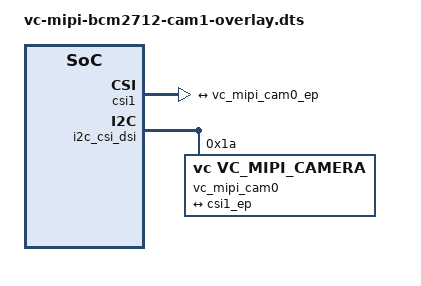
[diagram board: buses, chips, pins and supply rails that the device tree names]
//
// Definitions for cam 0 for RaspberryPi 5
//
// Copyright (C) 2024 - Florian Schmid, Vision Components GmbH
//




/dts-v1/;
/plugin/;

/ {    
	fragment@0 {
		target = <&csi1>;
		__overlay__ {
			status = "okay";

			port {
				csi1_ep: endpoint {
					remote-endpoint = <&vc_mipi_cam0_ep>;
					data-lanes = <1>;
				};
			};
		};
	};	
	fragment@1 {
		target = <&i2c_csi_dsi>;
		__overlay__ {
			#address-cells = <1>;
			#size-cells = <0>;
			status = "okay";

			vc_mipi_cam0: camera@1a {
				compatible = "vc,vc_mipi_camera";
				reg = <0x1a>;
				status = "okay";

				
				port {
					vc_mipi_cam0_ep: endpoint {
						remote-endpoint = <&csi1_ep>;
						data-lanes = <1>;

					};
				};
			};
		};
	};

	fragment@1001 {
		target = <&i2c_csi_dsi>;
		__dormant__ {
			camera@1a {
				port {
						endpoint {
							data-lanes = <1>;

						};
					};
				};
		};
	};
	fragment@1002 {
		target = <&i2c_csi_dsi>;
		__dormant__ {
			camera@1a {
				port {
						endpoint {
							data-lanes = <1 2>;

						};
					};
				};
		};
	};
	fragment@1004 {
		target = <&i2c_csi_dsi>;
		__dormant__ {
			camera@1a {
				port {
						endpoint {
							data-lanes = <1 2 3 4>;

						};
					};
				};
		};
	};
	fragment@2001 {
		target = <&csi1>;
		__dormant__ {
			status = "okay";
			port {
				endpoint {
					data-lanes = <1>;

				};
			};
		};
	};
	fragment@2002 {
		target = <&csi1>;
		__dormant__ {
			status = "okay";
			port {
				endpoint {
					data-lanes = <1 2>;

				};
			};
		};
	};
	fragment@2004 {
		target = <&csi1>;
		__dormant__ {
			status = "okay";
			port {
				endpoint {
					data-lanes = <1 2 3 4>;

				};
			};
		};
	};
	__overrides__ {
        lanes1 =       <0>,"+1=1001=2001";
		lanes2 =       <0>,"+1=1002=2002";
		lanes4 =       <0>,"+1=1004=2004";

    };
};


